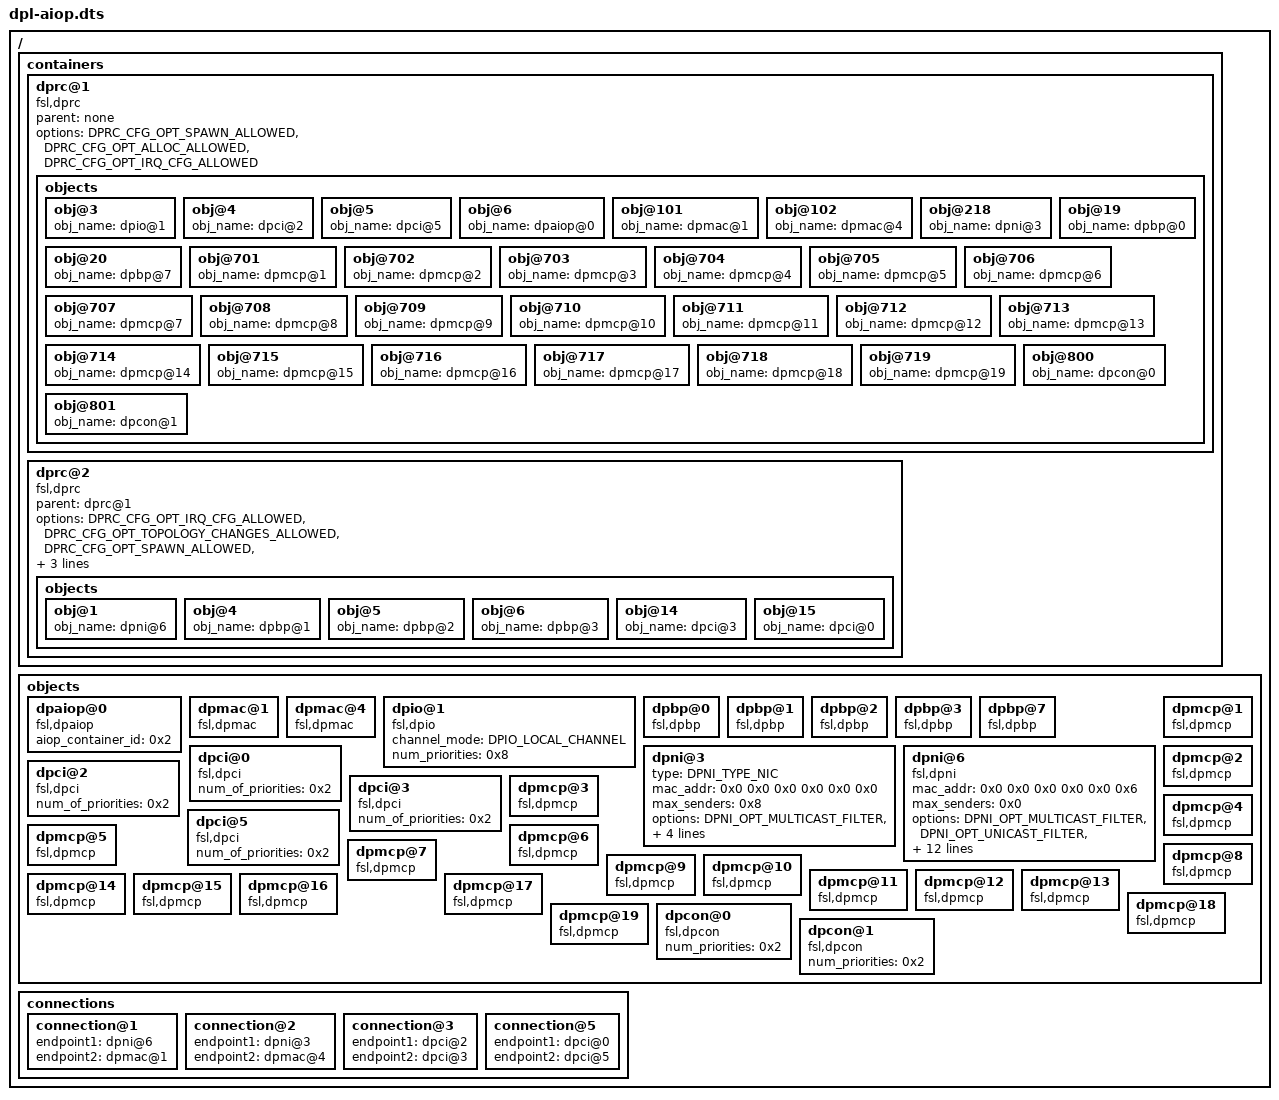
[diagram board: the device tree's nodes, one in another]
/*
 * Copyright 2017 NXP
 *
 * Redistribution and use in source and binary forms, with or without
 * modification, are permitted provided that the following conditions are met:
 *   * Redistributions of source code must retain the above copyright
 *     notice, this list of conditions and the following disclaimer.
 *   * Redistributions in binary form must reproduce the above copyright
 *     notice, this list of conditions and the following disclaimer in the
 *     documentation and/or other materials provided with the distribution.
 *   * Neither the name of the above-listed copyright holders nor the
 *     names of any contributors may be used to endorse or promote products
 *     derived from this software without specific prior written permission.
 *
 * THIS SOFTWARE IS PROVIDED BY THE COPYRIGHT HOLDERS AND CONTRIBUTORS "AS IS"
 * AND ANY EXPRESS OR IMPLIED WARRANTIES, INCLUDING, BUT NOT LIMITED TO, THE
 * IMPLIED WARRANTIES OF MERCHANTABILITY AND FITNESS FOR A PARTICULAR PURPOSE
 * ARE DISCLAIMED. IN NO EVENT SHALL THE COPYRIGHT HOLDERS OR CONTRIBUTORS BE
 * LIABLE FOR ANY DIRECT, INDIRECT, INCIDENTAL, SPECIAL, EXEMPLARY, OR
 * CONSEQUENTIAL DAMAGES (INCLUDING, BUT NOT LIMITED TO, PROCUREMENT OF
 * SUBSTITUTE GOODS OR SERVICES; LOSS OF USE, DATA, OR PROFITS; OR BUSINESS
 * INTERRUPTION) HOWEVER CAUSED AND ON ANY THEORY OF LIABILITY, WHETHER IN
 * CONTRACT, STRICT LIABILITY, OR TORT (INCLUDING NEGLIGENCE OR OTHERWISE)
 * ARISING IN ANY WAY OUT OF THE USE OF THIS SOFTWARE, EVEN IF ADVISED OF THE
 * POSSIBILITY OF SUCH DAMAGE.
 */
/dts-v1/;

/ {
	containers {

		dprc@1 {
			compatible = "fsl,dprc";
			parent = "none";
			options = "DPRC_CFG_OPT_SPAWN_ALLOWED", "DPRC_CFG_OPT_ALLOC_ALLOWED", "DPRC_CFG_OPT_IRQ_CFG_ALLOWED";

			objects {

				obj@3 {
					obj_name = "dpio@1";
				};

				obj@4 {
					obj_name = "dpci@2";
				};

				obj@5 {
					obj_name = "dpci@5";
				};

				obj@6 {
					obj_name = "dpaiop@0";
				};

				obj@101 {
					obj_name = "dpmac@1";
				};

				obj@102 {
					obj_name = "dpmac@4";
				};

				obj@218 {
					obj_name = "dpni@3";
				};

				obj@19 {
					obj_name = "dpbp@0";
				};

				obj@20 {
					obj_name = "dpbp@7";
				};

				obj@701 {
					obj_name = "dpmcp@1";
				};

				obj@702 {
					obj_name = "dpmcp@2";
				};

				obj@703 {
					obj_name = "dpmcp@3";
				};

				obj@704 {
					obj_name = "dpmcp@4";
				};

				obj@705 {
					obj_name = "dpmcp@5";
				};

				obj@706 {
					obj_name = "dpmcp@6";
				};

				obj@707 {
					obj_name = "dpmcp@7";
				};

				obj@708 {
					obj_name = "dpmcp@8";
				};

				obj@709 {
					obj_name = "dpmcp@9";
				};

				obj@710 {
					obj_name = "dpmcp@10";
				};

				obj@711 {
					obj_name = "dpmcp@11";
				};

				obj@712 {
					obj_name = "dpmcp@12";
				};

				obj@713 {
					obj_name = "dpmcp@13";
				};

				obj@714 {
					obj_name = "dpmcp@14";
				};

				obj@715 {
					obj_name = "dpmcp@15";
				};

				obj@716 {
					obj_name = "dpmcp@16";
				};

				obj@717 {
					obj_name = "dpmcp@17";
				};

				obj@718 {
					obj_name = "dpmcp@18";
				};

				obj@719 {
					obj_name = "dpmcp@19";
				};

				obj@800 {
					obj_name = "dpcon@0";
				};

				obj@801 {
					obj_name = "dpcon@1";
				};
			};
		};

		dprc@2 {
			compatible = "fsl,dprc";
			parent = "dprc@1";
			options = "DPRC_CFG_OPT_IRQ_CFG_ALLOWED", "DPRC_CFG_OPT_TOPOLOGY_CHANGES_ALLOWED", "DPRC_CFG_OPT_SPAWN_ALLOWED", "DPRC_CFG_OPT_ALLOC_ALLOWED", "DPRC_CFG_OPT_AIOP", "DPRC_CFG_OPT_OBJ_CREATE_ALLOWED";

			objects {

				obj@1 {
					obj_name = "dpni@6";
				};

				obj@4 {
					obj_name = "dpbp@1";
				};

				obj@5 {
					obj_name = "dpbp@2";
				};

				obj@6 {
					obj_name = "dpbp@3";
				};

				obj@14 {
					obj_name = "dpci@3";
				};

				obj@15 {
					obj_name = "dpci@0";
				};
			};
		};
	};

	objects {

		dpaiop@0 {
			compatible = "fsl,dpaiop";
			aiop_container_id = <0x2>;
		};

		dpmac@1 {
			compatible = "fsl,dpmac";
		};

		dpmac@4 {
			compatible = "fsl,dpmac";
		};

		dpio@1 {
			compatible = "fsl,dpio";
			channel_mode = "DPIO_LOCAL_CHANNEL";
			num_priorities = <0x8>;
		};

		dpbp@0 {
			compatible = "fsl,dpbp";
		};

		dpbp@1 {
			compatible = "fsl,dpbp";
		};

		dpbp@2 {
			compatible = "fsl,dpbp";
		};

		dpbp@3 {
			compatible = "fsl,dpbp";
		};

		dpbp@7 {
			compatible = "fsl,dpbp";
		};

		dpni@3 {
			type = "DPNI_TYPE_NIC";
			mac_addr = <0x0 0x0 0x0 0x0 0x0 0x0>;
			max_senders = <0x8>;
			options = "DPNI_OPT_MULTICAST_FILTER", "DPNI_OPT_UNICAST_FILTER";
			max_tcs = <0x1>;
			max_dist_per_tc = <0x0>;
			max_dist_key_size = <0x18>;
		};

		dpni@6 {
			compatible = "fsl,dpni";
			mac_addr = <0x0 0x0 0x0 0x0 0x0 0x6>;
			max_senders = <0x0>;
			options = "DPNI_OPT_MULTICAST_FILTER", "DPNI_OPT_UNICAST_FILTER", "DPNI_OPT_TX_CONF_DISABLED", "DPNI_OPT_DIST_HASH";
			max_tcs = <0x1>;
			max_policers = <0x1>;
			max_dist_per_tc = <0x0 0x0 0x0 0x0 0x0 0x0 0x0 0x0>;
			max_unicast_filters = <0x0>;
			max_multicast_filters = <0x0>;
			max_vlan_filters = <0x0>;
			max_qos_entries = <0x0>;
			max_qos_key_size = <0x0>;
			max_dist_key_size = <0x0>;
		};

		dpci@0 {
			compatible = "fsl,dpci";
			num_of_priorities = <0x2>;
		};

		dpci@2 {
			compatible = "fsl,dpci";
			num_of_priorities = <0x2>;
		};

		dpci@3 {
			compatible = "fsl,dpci";
			num_of_priorities = <0x2>;
		};

		dpci@5 {
			compatible = "fsl,dpci";
			num_of_priorities = <0x2>;
		};

		dpmcp@1 {
			compatible = "fsl,dpmcp";
		};

		dpmcp@2 {
			compatible = "fsl,dpmcp";
		};

		dpmcp@3 {
			compatible = "fsl,dpmcp";
		};

		dpmcp@4 {
			compatible = "fsl,dpmcp";
		};

		dpmcp@5 {
			compatible = "fsl,dpmcp";
		};

		dpmcp@6 {
			compatible = "fsl,dpmcp";
		};

		dpmcp@7 {
			compatible = "fsl,dpmcp";
		};

		dpmcp@8 {
			compatible = "fsl,dpmcp";
		};

		dpmcp@9 {
			compatible = "fsl,dpmcp";
		};

		dpmcp@10 {
			compatible = "fsl,dpmcp";
		};

		dpmcp@11 {
			compatible = "fsl,dpmcp";
		};

		dpmcp@12 {
			compatible = "fsl,dpmcp";
		};

		dpmcp@13 {
			compatible = "fsl,dpmcp";
		};

		dpmcp@14 {
			compatible = "fsl,dpmcp";
		};

		dpmcp@15 {
			compatible = "fsl,dpmcp";
		};

		dpmcp@16 {
			compatible = "fsl,dpmcp";
		};

		dpmcp@17 {
			compatible = "fsl,dpmcp";
		};

		dpmcp@18 {
			compatible = "fsl,dpmcp";
		};

		dpmcp@19 {
			compatible = "fsl,dpmcp";
		};

		dpcon@0 {
			compatible = "fsl,dpcon";
			num_priorities = <0x2>;
		};

		dpcon@1 {
			compatible = "fsl,dpcon";
			num_priorities = <0x2>;
		};
	};

	connections {

		connection@1 {
			endpoint1 = "dpni@6";
			endpoint2 = "dpmac@1";
		};

		connection@2 {
			endpoint1 = "dpni@3";
			endpoint2 = "dpmac@4";
		};

		connection@3 {
			endpoint1 = "dpci@2";
			endpoint2 = "dpci@3";
		};

		connection@5 {
			endpoint1 = "dpci@0";
			endpoint2 = "dpci@5";
		};
	};
};
